# STM32U375 register map
File version: 1.0
CPU: CM33 r0p1, little endian, MPU, FPU, 4 interrupt priority bits
Registers are 32-bit, read-write, reset 0x0 unless marked. A register's access mark holds for its fields unless they carry their own. Offsets are from the block's base; [hi:lo] are bit positions; {n}, {i} and the like mark numbered series.

## ExTI — ExTI address block description
Base 0x40032000
Same registers: SEC_ExTI 0x50032000
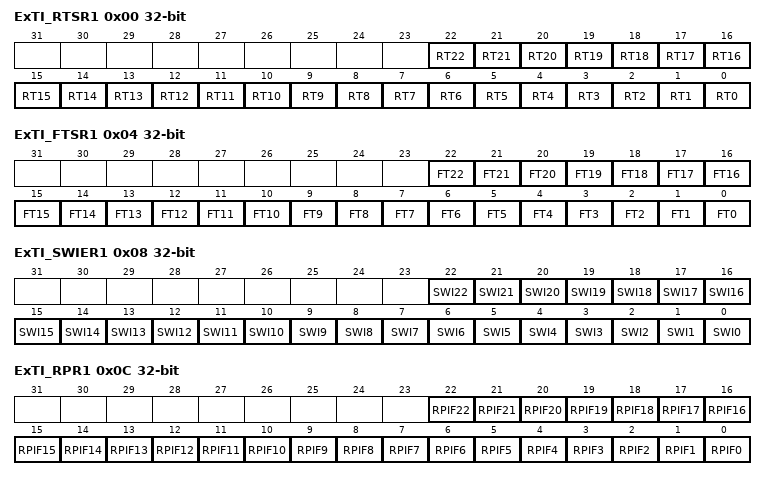
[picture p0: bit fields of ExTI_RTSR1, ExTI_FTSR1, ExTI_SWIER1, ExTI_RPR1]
0x00 ExTI_RTSR1 — ExTI rising trigger selection register
  [all] fields
    0=Rising trigger disabled (for event and interrupt) for input line; 1=Rising trigger enabled (for event and interrupt) for input line
  [n] RT{n} (n=0..22) — Rising trigger event configuration bit of configurable event input i
0x04 ExTI_FTSR1 — ExTI falling trigger selection register
  [all] fields
    0=Falling trigger disabled (for event and interrupt) for input line; 1=Falling trigger enabled (for event and interrupt) for input line
  [n] FT{n} (n=0..22) — Falling trigger event configuration bit of configurable event input i
0x08 ExTI_SWIER1 — ExTI software interrupt event register
  [all] fields
    0=Writing 0 has no effect; 1=Writing 1 triggers a rising edge event on event i
  [n] SWI{n} (n=0..22) — Software interrupt on event i
0x0C ExTI_RPR1 — ExTI rising edge pending register
  [all] fields
    0=No rising edge trigger request occurred; 1=Rising edge trigger request occurred
  [n] RPIF{n} (n=0..22) — Configurable event input i rising edge pending bit
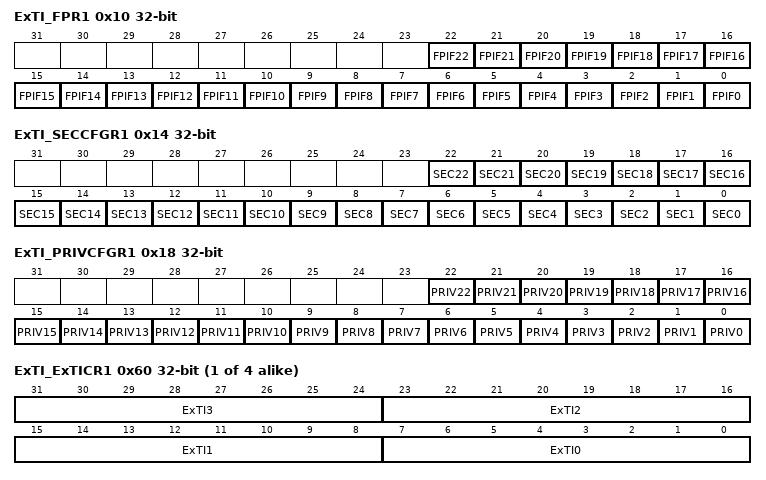
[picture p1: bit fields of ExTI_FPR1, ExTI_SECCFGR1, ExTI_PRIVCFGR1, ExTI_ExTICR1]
0x10 ExTI_FPR1 — ExTI falling edge pending register
  [all] fields
    0=No falling edge trigger request occurred; 1=Falling edge trigger request occurred
  [n] FPIF{n} (n=0..22) — configurable event inputs i falling edge pending bit
0x14 ExTI_SECCFGR1 — ExTI security configuration register
  [all] fields
    0=Event security disabled (nonsecure); 1=Event security enabled (secure)
  [n] SEC{n} (n=0..22) — Security enable on event input i
0x18 ExTI_PRIVCFGR1 — ExTI privilege configuration register
  [all] fields
    0=Event privilege disabled (unprivileged); 1=Event privilege enabled (privileged)
  [n] PRIV{n} (n=0..22) — Security enable on event input i
{0x5C+4i} ExTI_ExTICR{i} (i=1..4) — ExTI external interrupt selection register
  [31:24] ExTI{4i-1} — ExTI{4i-1} GPIO port selection
    0=PA[{4i-1}] pin; 1=PB[{4i-1}] pin; 2=PC[{4i-1}] pin; 3=PD[{4i-1}] pin; 4=PE[{4i-1}] pin; 6=PG[{4i-1}] pin; 7=PH[{4i-1}] pin
  [23:16] ExTI{4i-2} — ExTI{4i-2} GPIO port selection
    0=PA[{4i-2}] pin; 1=PB[{4i-2}] pin; 2=PC[{4i-2}] pin; 3=PD[{4i-2}] pin; 4=PE[{4i-2}] pin; 6=PG[{4i-2}] pin; 7=PH[{4i-2}] pin
  [15:8] ExTI{4i-3}
  [7:0] ExTI{4i-4}
0x70 ExTI_LOCKR — ExTI lock register
  [0] LOCK — Global security and privilege configuration registers (ExTI_SECCFGR and ExTI_PRIVCFGR) lock
    0=Security and privilege configuration open, can be modified; 1=Security and privilege configuration locked, can no longer be modified
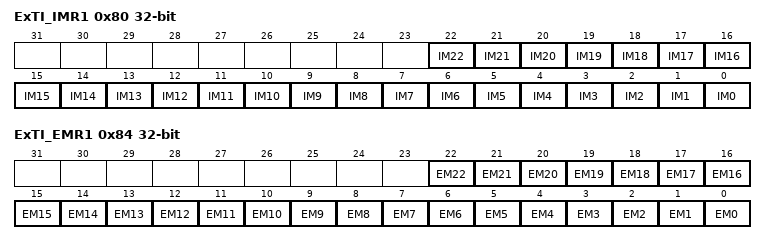
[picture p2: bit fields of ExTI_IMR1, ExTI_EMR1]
0x80 ExTI_IMR1 — ExTI CPU wake-up with interrupt mask register
  [all] fields
    0=Wake-up with interrupt request from input event i is masked; 1=Wake-up with interrupt request from input event i is unmasked
  [n] IM{n} (n=0..22) — CPU wake-up with interrupt mask on event input i
0x84 ExTI_EMR1 — ExTI CPU wake-up with event mask register
  [all] fields
    0=Wake-up with event generation from line i is masked; 1=Wake-up with event generation from line i is unmasked
  [n] EM{n} (n=0..22) — CPU wake-up with event generation mask on event input i

## GTZC1_MPCBB1 — GTZC1_MPCBB1 Address block
Base 0x40032C00
Same registers: SEC_GTZC1_MPCBB1 0x50032C00
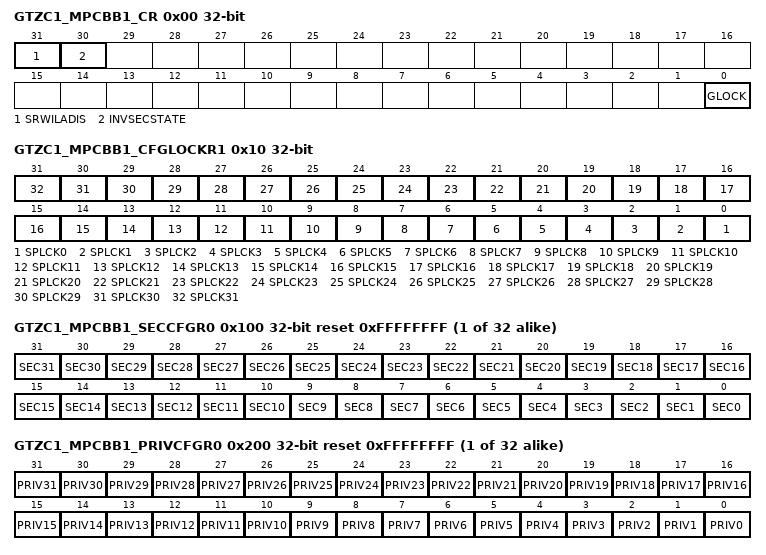
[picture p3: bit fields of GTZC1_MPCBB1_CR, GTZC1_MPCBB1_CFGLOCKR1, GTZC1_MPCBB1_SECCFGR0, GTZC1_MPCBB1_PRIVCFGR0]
0x00 GTZC1_MPCBB1_CR — GTZC1 SRAM1 MPCBB control register
  [31] SRWILADIS — This bit disables the detection of an illegal access when a secure read/write transaction access a non-secure blocks of the block-based SRAM (secure fetch on non-secure block is always considered illegal). 0: enabled, secure read/write access not allowed on non-secure SRAM block 1: disabled, secure read/write access allowed on non-secure SRAM block
    0=enabled, secure read/write access not allowed on non-secure SRAM block; 1=disabled, secure read/write access allowed on non-secure SRAM block
  [30] INVSECSTATE — This bit is used to define the internal SRAMs clocks control in RCC as secure or not. 0: SRAMs clocks are secure if a secure area exists in the MPCBB. It is non secure if there is no secure area. 1: SRAMs clocks are non-secure even if a secure area exists in the MPCBB, and secure even if no secure block is set in the MPCBB.
    0=SRAMs clocks are secure if a secure area exists in the MPCBB. It is non secure if there is no secure area.; 1=SRAMs clocks are non-secure even if a secure area exists in the MPCBB, and secure even if no secure block is set in the MPCBB
  [0] GLOCK — This bit is cleared by default and once set, it can not be reset until system reset. 0: control register not locked 1: control register locked
    0=control register not locked; 1=control register locked
0x10 GTZC1_MPCBB1_CFGLOCKR1 — GTZC1 SRAM1 MPCBB configuration lock register 1
  [n] SPLCK{n} (n=0..31) — This bit is set by software and can be cleared only by system reset. 0: GTZC1_MPCBB1_SECCFGR{n} and GTZC1_MPCBB1_PRIVCFGR{n} can be written. 1: Writes to GTZC1_MPCBB1_SECCFGR{n} and GTZC1_MPCBB1_PRIVCFGR{n} are ignored
    0=GTZC1_MPCBB1_SECCFGR{n} and GTZC1_MPCBB1_PRIVCFGR{n} can be written; 1=Writes to GTZC1_MPCBB1_SECCFGR{n} and GTZC1_MPCBB1_PRIVCFGR{n} are ignored
{0x100+4i} GTZC1_MPCBB1_SECCFGR{i} reset 0xFFFFFFFF (i=0..31) — GTZC1 SRAM1 MPCBB security configuration for super-block {i} register
  [n] SEC{n} (n=0..31) — Unprivileged write to this bit is ignored if PRIV{n} bit is set in GTZC1_MPCBB1_PRIVCFGR{i}. Writes are ignored if SPLCK{i} bit is set in GTZC1_MPCBB1_CFGLOCKR1. 0: Non-secure access only to block {n}, belonging to super-block {i}. Secure access is also allowed if the SRWILADIS bit is set in GTZC1_MPCBBz_CR. 1: Secure access only to block {n}, belonging to super-block {i}.
    0=Non-secure access only to block {n}, belonging to super-block {i}. Secure access is also allowed if the SRWILADIS bit is set in GTZC1_MPCBBz_CR.; 1=Secure access only to block {n}, belonging to super-block {i}
{0x200+4i} GTZC1_MPCBB1_PRIVCFGR{i} reset 0xFFFFFFFF (i=0..31) — GTZC1 SRAM1 MPCBB privileged configuration for super-block {i} register
  [n] PRIV{n} (n=0..31) — Non-secure write to this bit is ignored if SEC{n} bit is set in GTZC1_MPCBB1_SECCFGR{i}. Writes are ignored if SPLCK{i} bit is set in GTZC1_MPCBB1_CFGLOCKR1. 0: Privileged and unprivileged access to block {n}, belonging to super-block {i} 1: Only privileged access to block {n}, belonging to super-block {i}
    0=Privileged and unprivileged access to block {n}, belonging to super-block {i}; 1=Only privileged access to block {n}, belonging to super-block {i}
